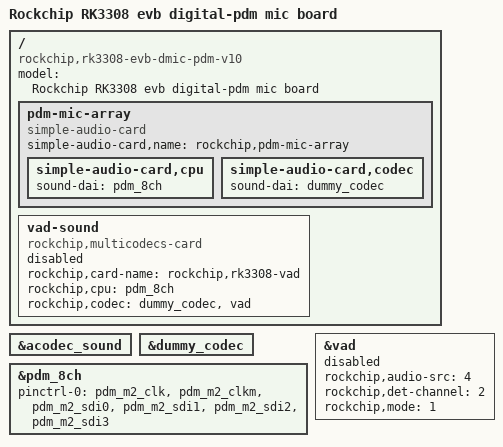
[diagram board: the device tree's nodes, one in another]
/*
 * Copyright (c) 2018 Fuzhou Rockchip Electronics Co., Ltd
 *
 * SPDX-License-Identifier: (GPL-2.0+ OR MIT)
 */

/dts-v1/;

#include "rk3308-evb-v10.dtsi"

/ {
	model = "Rockchip RK3308 evb digital-pdm mic board";
	compatible = "rockchip,rk3308-evb-dmic-pdm-v10", "rockchip,rk3308";

	pdm-mic-array {
		status = "okay";
		compatible = "simple-audio-card";
		simple-audio-card,name = "rockchip,pdm-mic-array";
		simple-audio-card,cpu {
			sound-dai = <&pdm_8ch>;
		};
		simple-audio-card,codec {
			sound-dai = <&dummy_codec>;
		};
	};

	vad-sound {
		status = "disabled";
		compatible = "rockchip,multicodecs-card";
		rockchip,card-name = "rockchip,rk3308-vad";
		rockchip,cpu = <&pdm_8ch>;
		rockchip,codec = <&dummy_codec>, <&vad>;
	};
};

&acodec_sound {
	status = "okay";
};

&dummy_codec {
	status = "okay";
	#sound-dai-cells = <0>;
};

&pdm_8ch {
	status = "okay";
	#sound-dai-cells = <0>;
	pinctrl-names = "default";
	pinctrl-0 = <&pdm_m2_clk
		     &pdm_m2_clkm
		     &pdm_m2_sdi0
		     &pdm_m2_sdi1
		     &pdm_m2_sdi2
		     &pdm_m2_sdi3>;
};

&vad {
	status = "disabled";
	rockchip,audio-src = <4>;
	rockchip,det-channel = <2>;
	rockchip,mode = <1>;
	#sound-dai-cells = <0>;
};
